AUTOSAR XML (schema 4-3-0)
package /App_NvM
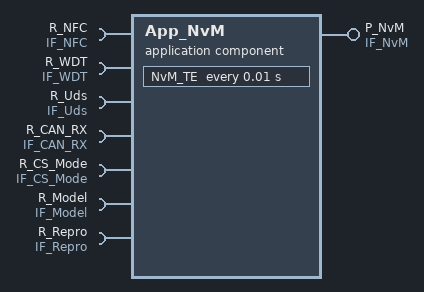
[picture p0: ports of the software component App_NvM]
  application sw component type App_NvM  # NvM R/W 제어
    6 x require port:
      R_NFC: nonqueued-receiver-com-spec=NFC_STR, required-interface=IF_NFC
      R_WDT: nonqueued-receiver-com-spec=WDT_STR, required-interface=IF_WDT
      R_Uds: nonqueued-receiver-com-spec=Uds_STR, required-interface=IF_Uds
      R_CAN_RX: nonqueued-receiver-com-spec=CAN_RX_STR, required-interface=IF_CAN_RX
      R_CS_Mode: required-com-specs=[ModeInit, NvMInit, ApplicationInit], required-interface=IF_CS_Mode  # None
      R_Model: nonqueued-receiver-com-spec=Model_STR, required-interface=IF_Model
    provide port P_NvM: nonqueued-sender-com-spec=NvM_STR, provided-interface=IF_NvM  # None
    require port R_Repro: nonqueued-receiver-com-spec=Repro_STR, required-interface=IF_Repro
    behavior IB_Mdw_NvM: data-type-mapping=DataTypeMappingSet_WPC, handle-termination-and-restart=NO-SUPPORT, included-data-type-set=data-type=IDT_ENUM_WPCStatus  # Middleware NvM IB
      timing event TE_NvM_TE: start-on-event=NvM_TE, period=0.01
      runnable NvM_TE: symbol=NvM_TE_Runnable
        data-receive-point-by-arguments:
          6 x access, all with scope=COMMUNICATION-INTER-ECU:
            DRPBA_NvM_TE_R_BCAN_RX_u8_arr: accessed-variable=R_CAN_RX.CAN_RX_STR
            DRPBA_NvM_TE_R_Model_Structure: accessed-variable=R_Model.Model_STR
            DRPBA_NvM_TE_R_Uds_Uds_STR: accessed-variable=R_Uds.Uds_STR
            DRPBA_NvM_TE_R_WDT_WDT_STR: accessed-variable=R_WDT.WDT_STR
            DRPBA_NvM_TE_R_NFC_NFC_STR: accessed-variable=R_NFC.NFC_STR
            DRPBA_NvM_TE_R_Repro_Repro_STR: accessed-variable=R_Repro.Repro_STR
        data-send-points:
          access DSP_NvM_TE_P_NvM_NvM_u8_arr: accessed-variable=P_NvM.NvM_STR, scope=COMMUNICATION-INTER-ECU
        sync call SSCP_R_CS_Mode_ModeInit: operation=R_CS_Mode.ModeInit, timeout=0.0
        sync call SSCP_R_CS_Mode_NvMInit: operation=R_CS_Mode.NvMInit, timeout=0.0
        sync call SSCP_R_CS_Mode_ApplicationInit: operation=R_CS_Mode.ApplicationInit, timeout=0.0
  sender receiver interface IF_NvM  # NFC SWC Output
    data NvM_STR: type=IDT_NvM_STR
